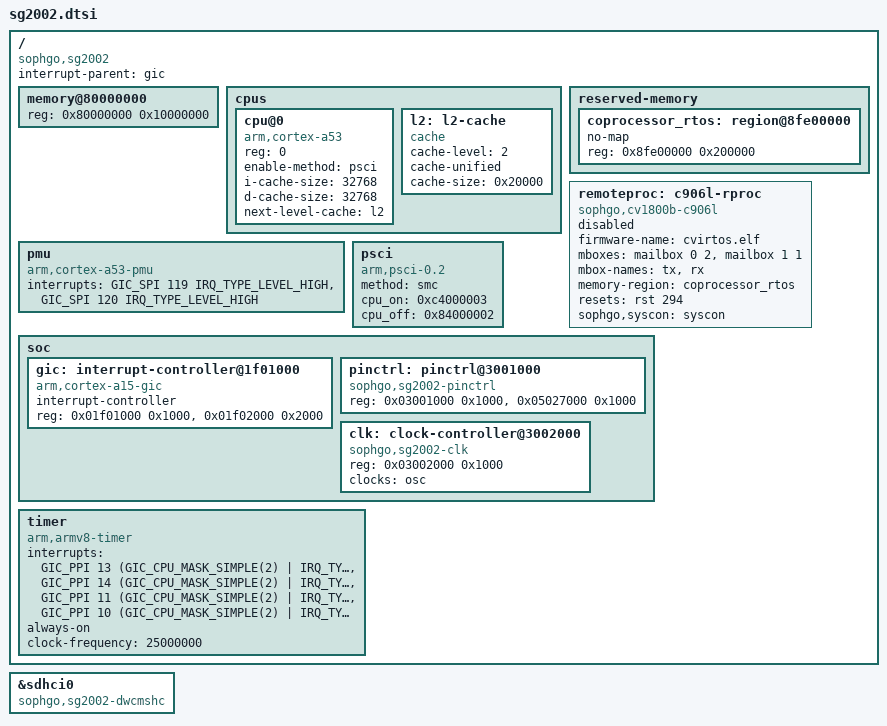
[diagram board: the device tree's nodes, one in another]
// SPDX-License-Identifier: (GPL-2.0 OR MIT)
/*
 * Copyright (C) 2024 Thomas Bonnefille <thomas.bonnefille@bootlin.com>
 *
 * SG2002 (CV181x) SoC description for the ARM64 (Cortex-A53) core.
 *
 * Mirrors arch/riscv/boot/dts/sophgo/sg2002.dtsi, with two changes:
 *
 *  - The peripheral interrupts are GIC SPIs, not the RISC-V PLIC's local
 *    interrupt numbers, so SOC_PERIPHERAL_IRQ() is redefined the same way
 *    upstream's arch/arm64/boot/dts/sophgo/sg2000.dtsi does it. The SoC
 *    description itself (cv180x.dtsi, cv181x.dtsi) is shared with the
 *    RISC-V side and included from there.
 *
 *  - The CPU is an ARM Cortex-A53, not a T-Head C906, so the cpu nodes
 *    come from here rather than from cv180x-cpus.dtsi, and there is no
 *    PLIC/CLINT - the GIC replaces them.
 */

#define SOC_PERIPHERAL_IRQ(nr)		GIC_SPI (nr)

#include <dt-bindings/interrupt-controller/arm-gic.h>
#include <dt-bindings/pinctrl/pinctrl-sg2002.h>
#include <riscv/sophgo/cv180x.dtsi>
#include <riscv/sophgo/cv181x.dtsi>

/ {
	compatible = "sophgo,sg2002";
	interrupt-parent = <&gic>;

	memory@80000000 {
		device_type = "memory";
		reg = <0x80000000 0x10000000>;	/* 256MiB */
	};

	cpus {
		#address-cells = <1>;
		#size-cells = <0>;

		cpu@0 {
			compatible = "arm,cortex-a53";
			device_type = "cpu";
			reg = <0>;
			enable-method = "psci";
			i-cache-size = <32768>;
			d-cache-size = <32768>;
			next-level-cache = <&l2>;
		};

		l2: l2-cache {
			compatible = "cache";
			cache-level = <2>;
			cache-unified;
			cache-size = <0x20000>;
		};
	};

	reserved-memory {
		#address-cells = <1>;
		#size-cells = <1>;
		ranges;

		coprocessor_rtos: region@8fe00000 {
			no-map;
			reg = <0x8fe00000 0x200000>;
		};
	};

	remoteproc: c906l-rproc {
		compatible = "sophgo,cv1800b-c906l";
		firmware-name = "cvirtos.elf";
		mboxes = <&mailbox 0 2>, <&mailbox 1 1>;
		mbox-names = "tx", "rx";
		memory-region = <&coprocessor_rtos>;
		resets = <&rst 294>;
		sophgo,syscon = <&syscon>;
		status = "disabled";
	};

	pmu {
		compatible = "arm,cortex-a53-pmu";
		interrupts = <GIC_SPI 119 IRQ_TYPE_LEVEL_HIGH>,
			     <GIC_SPI 120 IRQ_TYPE_LEVEL_HIGH>;
	};

	psci {
		compatible = "arm,psci-0.2";
		method = "smc";
		cpu_on = <0xc4000003>;
		cpu_off = <0x84000002>;
	};

	soc {
		gic: interrupt-controller@1f01000 {
			compatible = "arm,cortex-a15-gic";
			interrupt-controller;
			#interrupt-cells = <3>;
			reg = <0x01f01000 0x1000>,
			      <0x01f02000 0x2000>;
		};

		pinctrl: pinctrl@3001000 {
			compatible = "sophgo,sg2002-pinctrl";
			reg = <0x03001000 0x1000>,
			      <0x05027000 0x1000>;
			reg-names = "sys", "rtc";
		};

		clk: clock-controller@3002000 {
			compatible = "sophgo,sg2002-clk", "sophgo,sg2000-clk";
			reg = <0x03002000 0x1000>;
			clocks = <&osc>;
			#clock-cells = <1>;
		};
	};

	timer {
		compatible = "arm,armv8-timer";
		interrupts = <GIC_PPI 13 (GIC_CPU_MASK_SIMPLE(2) | IRQ_TYPE_LEVEL_LOW)>,
			     <GIC_PPI 14 (GIC_CPU_MASK_SIMPLE(2) | IRQ_TYPE_LEVEL_LOW)>,
			     <GIC_PPI 11 (GIC_CPU_MASK_SIMPLE(2) | IRQ_TYPE_LEVEL_LOW)>,
			     <GIC_PPI 10 (GIC_CPU_MASK_SIMPLE(2) | IRQ_TYPE_LEVEL_LOW)>;
		always-on;
		clock-frequency = <25000000>;
	};
};

&sdhci0 {
	compatible = "sophgo,sg2002-dwcmshc";
};
